VERSION ""

NS_ :

BS_:

BU_: XXX 0

BO_ 1362 NEW_MSG_1: 8 XXX
 SG_ NEW_SIGNAL_1 : 24|8@1+ (1,0) [0|255] "" XXX
 SG_ NEW_SIGNAL_2 : 56|8@1+ (1,0) [0|255] "" XXX

BO_ 1544 clim ?: 8 XXX
 SG_ NEW_SIGNAL_1 : 56|8@1+ (1,0) [0|255] "" XXX
 SG_ NEW_SIGNAL_2 : 48|7@1+ (1,0) [0|127] "" XXX

BO_ 973 BREAKS: 8 XXX
 SG_ b : 0|0@0+ (4,5) [0|6] "," 0

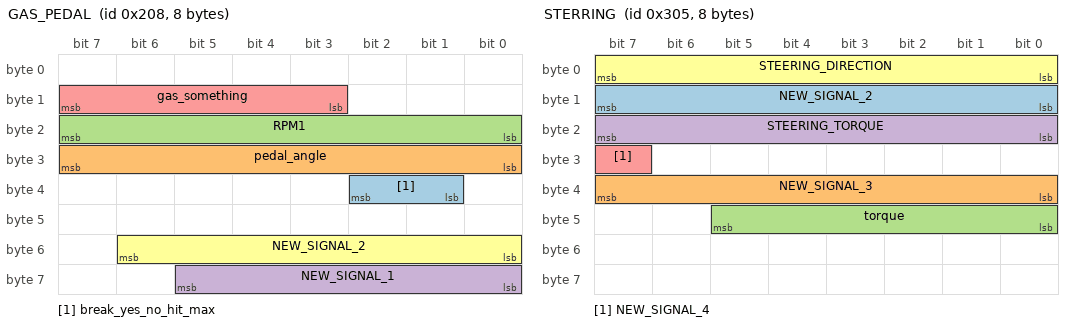
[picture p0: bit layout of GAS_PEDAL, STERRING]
BO_ 520 GAS_PEDAL: 8 XXX
 SG_ break_yes_no_hit_max : 33|2@1+ (1,0) [0|3] "" XXX
 SG_ pedal_angle : 24|8@1+ (1,0) [0|255] "" XXX
 SG_ RPM1 : 16|8@1+ (1,0) [0|255] "" XXX
 SG_ NEW_SIGNAL_1 : 56|6@1+ (1,0) [0|63] "" XXX
 SG_ gas_something : 11|5@1+ (1,0) [0|255] "" XXX
 SG_ NEW_SIGNAL_2 : 48|7@1+ (1,0) [0|127] "" XXX

BO_ 773 STERRING: 8 XXX
 SG_ NEW_SIGNAL_2 : 8|8@1+ (1,0) [0|255] "" XXX
 SG_ NEW_SIGNAL_3 : 32|8@1+ (1,0) [0|255] "" XXX
 SG_ torque : 40|6@1+ (1,0) [0|63] "" XXX
 SG_ STEERING_TORQUE : 16|8@1+ (1,0) [0|255] "" XXX
 SG_ NEW_SIGNAL_4 : 31|1@0+ (1,0) [0|1] "" XXX
 SG_ STEERING_DIRECTION : 0|8@1+ (1,0) [0|255] "" XXX

BO_ 1042 Radio: 8 XXX

BO_ 1074 NEW_MSG_3: 8 XXX

BO_ 1960 Lights: 8 XXX

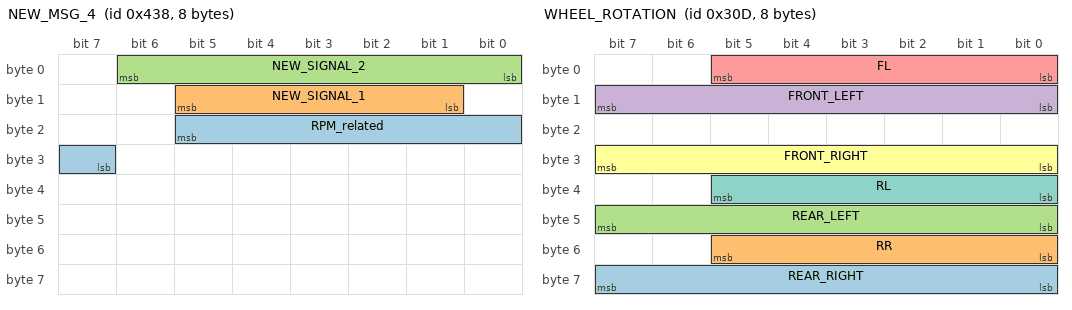
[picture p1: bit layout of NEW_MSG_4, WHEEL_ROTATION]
BO_ 1080 NEW_MSG_4: 8 XXX
 SG_ RPM_related : 21|7@0+ (1,0) [0|127] "" XXX
 SG_ NEW_SIGNAL_1 : 9|5@1+ (1,0) [0|31] "" XXX
 SG_ NEW_SIGNAL_2 : 0|7@1+ (1,0) [0|63] "" XXX

BO_ 845 NEW_MSG_5: 8 XXX
 SG_ change_onstop : 56|7@1+ (0,0) [0|255] "" XXX
 SG_ NEW_SIGNAL_1 : 40|4@1+ (1,0) [0|15] "" XXX

BO_ 841 NEW_MSG_6: 8 XXX
 SG_ NEW_SIGNAL_1 : 56|8@1+ (1,0) [0|255] "" XXX

BO_ 781 WHEEL_ROTATION: 8 XXX
 SG_ REAR_RIGHT : 56|8@1+ (1,0) [0|255] "" XXX
 SG_ RR : 48|6@1+ (1,0) [0|7] "" XXX
 SG_ REAR_LEFT : 47|8@0+ (1,0) [0|127] "" XXX
 SG_ FRONT_LEFT : 8|8@1+ (1,0) [0|255] "" XXX
 SG_ FL : 0|6@1+ (1,0) [0|63] "" XXX
 SG_ FRONT_RIGHT : 24|8@1+ (1,0) [0|255] "" XXX
 SG_ RL : 32|6@1+ (1,0) [0|63] "" XXX

BO_ 1299 NEW_MSG_7: 8 XXX
 SG_ NEW_SIGNAL_1 : 56|8@1+ (1,0) [0|255] "" XXX
 SG_ NEW_SIGNAL_2 : 16|8@1+ (1,0) [0|255] "" XXX

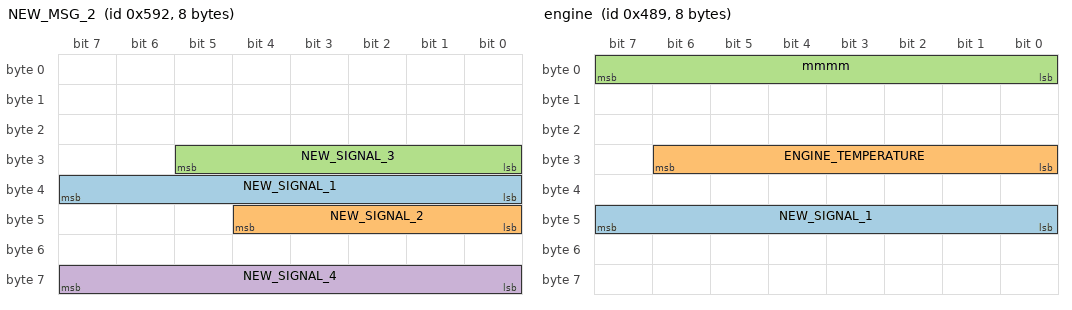
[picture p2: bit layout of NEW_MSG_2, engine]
BO_ 1426 NEW_MSG_2: 8 XXX
 SG_ NEW_SIGNAL_1 : 32|8@1+ (1,0) [0|255] "" XXX
 SG_ NEW_SIGNAL_2 : 40|5@1+ (1,0) [0|31] "" XXX
 SG_ NEW_SIGNAL_3 : 24|6@1+ (1,0) [0|63] "" XXX
 SG_ NEW_SIGNAL_4 : 56|8@1+ (1,0) [0|255] "" XXX

BO_ 1416 rpm: 8 XXX
 SG_ NEW_SIGNAL_1 : 56|5@1+ (1,0) [0|31] "" XXX
 SG_ link_accel : 32|8@1+ (1,0) [0|255] "" XXX

BO_ 1293 NEW_MSG_8: 8 XXX

BO_ 1161 engine: 8 XXX
 SG_ NEW_SIGNAL_1 : 40|8@1+ (1,0) [0|255] "" XXX
 SG_ ENGINE_TEMPERATURE : 24|7@1+ (1,0) [0|127] "" XXX
 SG_ mmmm : 0|8@1+ (1,0) [0|255] "" XXX

CM_ SG_ 520 pedal_angle "0 when no pressure 200 when full press down";
CM_ SG_ 773 torque "reacts just after steering";
CM_ SG_ 773 STEERING_DIRECTION "250 IS RIGHT 0 IS LEFT";
CM_ SG_ 845 change_onstop "maybe someting to do with batery charging?";
